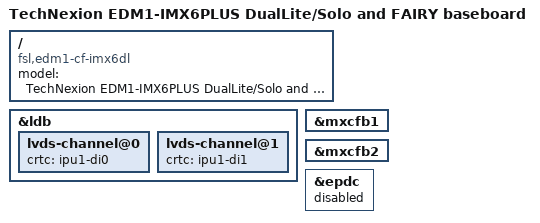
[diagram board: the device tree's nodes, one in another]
/*
 * Copyright 2017 Technexion Ltd.
 *
 * Author: Tapani Utriainen <tapani@technexion.com>
 *
 * This program is free software; you can redistribute it and/or modify
 * it under the terms of the GNU General Public License version 2 as
 * published by the Free Software Foundation.
 *
 */
/dts-v1/;
#define EDM2_ELF_ENABLE_SPDIF
#include <dt-bindings/interrupt-controller/irq.h>
#include "imx6dl.dtsi"
#include "imx6qdl-edm2-cf-pmic.dtsi"
#include "baseboard_edm2_elf.dtsi"

/ {
	model = "TechNexion EDM1-IMX6PLUS DualLite/Solo and FAIRY baseboard";
	compatible = "fsl,edm1-cf-imx6dl", "fsl,imx6dl";
};

&ldb {
	lvds-channel@0 {
		crtc = "ipu1-di0";
	};

	lvds-channel@1 {
		crtc = "ipu1-di1";
	};
};

&mxcfb1 {
	status = "okay";
};

&mxcfb2 {
	status = "okay";
};

#if 0
&mxcfb3 {
	status = "okay";
};

&mxcfb4 {
	status = "okay";
};
#endif

&epdc {
	status = "disabled";
};
